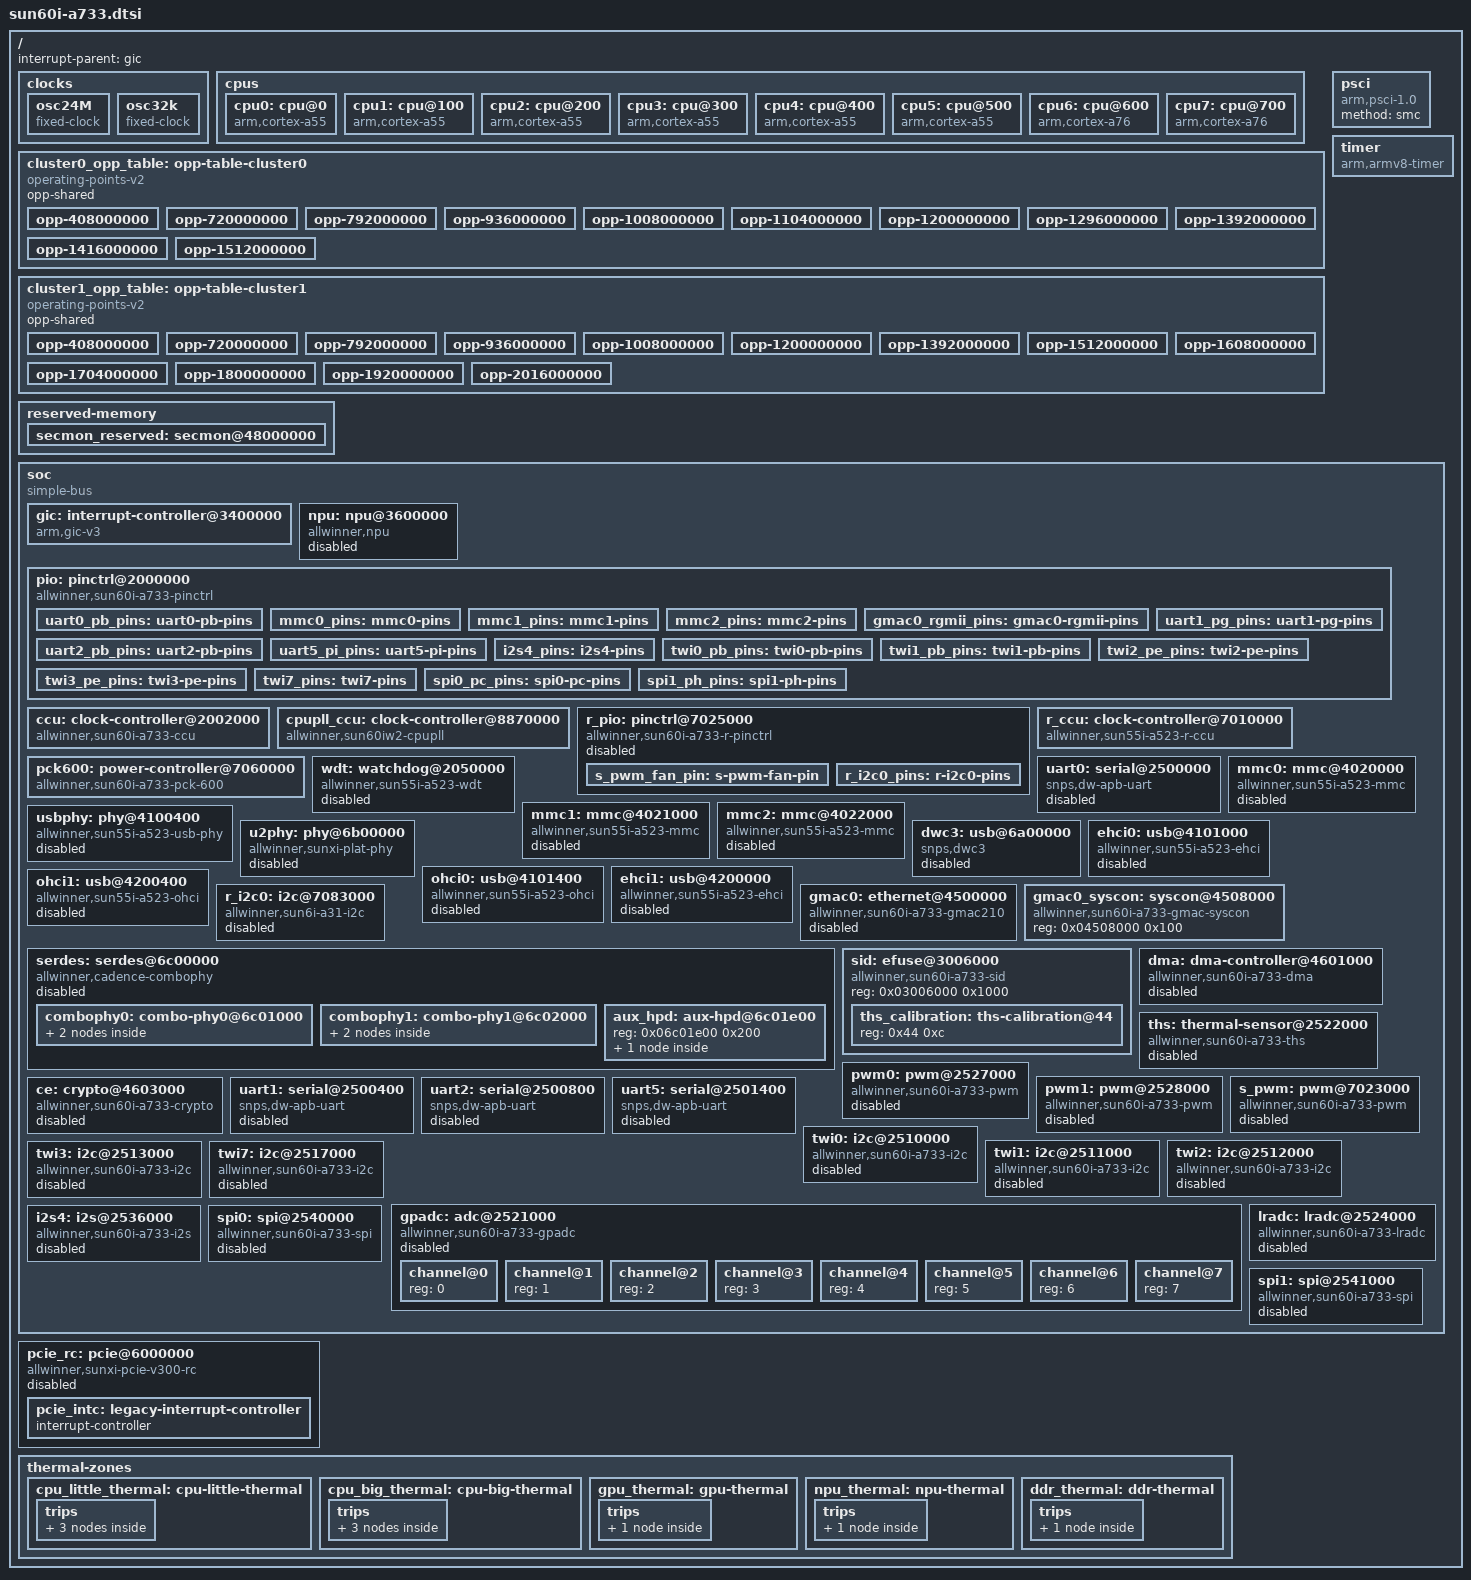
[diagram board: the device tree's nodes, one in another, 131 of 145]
// SPDX-License-Identifier: (GPL-2.0-only OR MIT)
/*
 * Copyright (C) 2026 Alastair D'Silva <alastair@d-silva.org>
 */

#include <dt-bindings/interrupt-controller/arm-gic.h>
#include <dt-bindings/clock/sun60i-a733-ccu.h>
#include <dt-bindings/clock/sun55i-a523-r-ccu.h>
#include <dt-bindings/reset/sun60i-a733-ccu.h>
#include <dt-bindings/reset/sun55i-a523-r-ccu.h>
#include <dt-bindings/power/allwinner,sun60i-a733-pck-600.h>
#include <dt-bindings/thermal/thermal.h>

#ifndef CLK_PLL_CPU_L
#define CLK_PLL_CPU_L 1
#endif
#ifndef CLK_PLL_CPU_B
#define CLK_PLL_CPU_B 2
#endif

/ {
	interrupt-parent = <&gic>;
	#address-cells = <2>;
	#size-cells = <2>;

	clocks {
		osc24M: osc24M {
			#clock-cells = <0>;
			compatible = "fixed-clock";
			clock-frequency = <24000000>;
			clock-output-names = "osc24M";
		};

		osc32k: osc32k {
			#clock-cells = <0>;
			compatible = "fixed-clock";
			clock-frequency = <32768>;
			clock-output-names = "osc32k";
		};
	};

	cpus {
		#address-cells = <2>;
		#size-cells = <0>;

		cpu0: cpu@0 {
			compatible = "arm,cortex-a55";
			device_type = "cpu";
			reg = <0x0 0x0>;
			enable-method = "psci";
			clocks = <&cpupll_ccu CLK_PLL_CPU_L>;
			operating-points-v2 = <&cluster0_opp_table>;
		};

		cpu1: cpu@100 {
			compatible = "arm,cortex-a55";
			device_type = "cpu";
			reg = <0x0 0x100>;
			enable-method = "psci";
			clocks = <&cpupll_ccu CLK_PLL_CPU_L>;
			operating-points-v2 = <&cluster0_opp_table>;
		};

		cpu2: cpu@200 {
			compatible = "arm,cortex-a55";
			device_type = "cpu";
			reg = <0x0 0x200>;
			enable-method = "psci";
			clocks = <&cpupll_ccu CLK_PLL_CPU_L>;
			operating-points-v2 = <&cluster0_opp_table>;
		};

		cpu3: cpu@300 {
			compatible = "arm,cortex-a55";
			device_type = "cpu";
			reg = <0x0 0x300>;
			enable-method = "psci";
			clocks = <&cpupll_ccu CLK_PLL_CPU_L>;
			operating-points-v2 = <&cluster0_opp_table>;
		};

		cpu4: cpu@400 {
			compatible = "arm,cortex-a55";
			device_type = "cpu";
			reg = <0x0 0x400>;
			enable-method = "psci";
			clocks = <&cpupll_ccu CLK_PLL_CPU_L>;
			operating-points-v2 = <&cluster0_opp_table>;
		};

		cpu5: cpu@500 {
			compatible = "arm,cortex-a55";
			device_type = "cpu";
			reg = <0x0 0x500>;
			enable-method = "psci";
			clocks = <&cpupll_ccu CLK_PLL_CPU_L>;
			operating-points-v2 = <&cluster0_opp_table>;
		};

		cpu6: cpu@600 {
			compatible = "arm,cortex-a76";
			device_type = "cpu";
			reg = <0x0 0x600>;
			enable-method = "psci";
			clocks = <&cpupll_ccu CLK_PLL_CPU_B>;
			operating-points-v2 = <&cluster1_opp_table>;
		};

		cpu7: cpu@700 {
			compatible = "arm,cortex-a76";
			device_type = "cpu";
			reg = <0x0 0x700>;
			enable-method = "psci";
			clocks = <&cpupll_ccu CLK_PLL_CPU_B>;
			operating-points-v2 = <&cluster1_opp_table>;
		};
	};

	cluster0_opp_table: opp-table-cluster0 {
		compatible = "operating-points-v2";
		opp-shared;

		opp-408000000 {
			opp-hz = /bits/ 64 <408000000>;
			opp-microvolt = <800000>;
			clock-latency-ns = <244144>;
		};

		opp-720000000 {
			opp-hz = /bits/ 64 <720000000>;
			opp-microvolt = <800000>;
			clock-latency-ns = <244144>;
		};

		opp-792000000 {
			opp-hz = /bits/ 64 <792000000>;
			opp-microvolt = <800000>;
			clock-latency-ns = <244144>;
		};

		opp-936000000 {
			opp-hz = /bits/ 64 <936000000>;
			opp-microvolt = <800000>;
			clock-latency-ns = <244144>;
		};

		opp-1008000000 {
			opp-hz = /bits/ 64 <1008000000>;
			opp-microvolt = <800000>;
			clock-latency-ns = <244144>;
		};

		opp-1104000000 {
			opp-hz = /bits/ 64 <1104000000>;
			opp-microvolt = <800000>;
			clock-latency-ns = <244144>;
		};

		opp-1200000000 {
			opp-hz = /bits/ 64 <1200000000>;
			opp-microvolt = <850000>;
			clock-latency-ns = <244144>;
		};

		opp-1296000000 {
			opp-hz = /bits/ 64 <1296000000>;
			opp-microvolt = <900000>;
			clock-latency-ns = <244144>;
		};

		opp-1392000000 {
			opp-hz = /bits/ 64 <1392000000>;
			opp-microvolt = <950000>;
			clock-latency-ns = <244144>;
		};

		opp-1416000000 {
			opp-hz = /bits/ 64 <1416000000>;
			opp-microvolt = <960000>;
			clock-latency-ns = <244144>;
		};

		opp-1512000000 {
			opp-hz = /bits/ 64 <1512000000>;
			opp-microvolt = <1000000>;
			clock-latency-ns = <244144>;
		};
	};

	cluster1_opp_table: opp-table-cluster1 {
		compatible = "operating-points-v2";
		opp-shared;

		opp-408000000 {
			opp-hz = /bits/ 64 <408000000>;
			opp-microvolt = <800000>;
			clock-latency-ns = <244144>;
		};

		opp-720000000 {
			opp-hz = /bits/ 64 <720000000>;
			opp-microvolt = <800000>;
			clock-latency-ns = <244144>;
		};

		opp-792000000 {
			opp-hz = /bits/ 64 <792000000>;
			opp-microvolt = <800000>;
			clock-latency-ns = <244144>;
		};

		opp-936000000 {
			opp-hz = /bits/ 64 <936000000>;
			opp-microvolt = <800000>;
			clock-latency-ns = <244144>;
		};

		opp-1008000000 {
			opp-hz = /bits/ 64 <1008000000>;
			opp-microvolt = <800000>;
			clock-latency-ns = <244144>;
		};

		opp-1200000000 {
			opp-hz = /bits/ 64 <1200000000>;
			opp-microvolt = <800000>;
			clock-latency-ns = <244144>;
		};

		opp-1392000000 {
			opp-hz = /bits/ 64 <1392000000>;
			opp-microvolt = <850000>;
			clock-latency-ns = <244144>;
		};

		opp-1512000000 {
			opp-hz = /bits/ 64 <1512000000>;
			opp-microvolt = <900000>;
			clock-latency-ns = <244144>;
		};

		opp-1608000000 {
			opp-hz = /bits/ 64 <1608000000>;
			opp-microvolt = <950000>;
			clock-latency-ns = <244144>;
		};

		opp-1704000000 {
			opp-hz = /bits/ 64 <1704000000>;
			opp-microvolt = <1000000>;
			clock-latency-ns = <244144>;
		};

		opp-1800000000 {
			opp-hz = /bits/ 64 <1800000000>;
			opp-microvolt = <1050000>;
			clock-latency-ns = <244144>;
		};

		opp-1920000000 {
			opp-hz = /bits/ 64 <1920000000>;
			opp-microvolt = <1100000>;
			clock-latency-ns = <244144>;
		};

		opp-2016000000 {
			opp-hz = /bits/ 64 <2016000000>;
			opp-microvolt = <1150000>;
			clock-latency-ns = <244144>;
		};
	};

	psci {
		compatible = "arm,psci-1.0";
		method = "smc";
	};

	timer {
		compatible = "arm,armv8-timer";
		interrupts = <GIC_PPI 13 IRQ_TYPE_LEVEL_LOW>,
			     <GIC_PPI 14 IRQ_TYPE_LEVEL_LOW>,
			     <GIC_PPI 11 IRQ_TYPE_LEVEL_LOW>,
			     <GIC_PPI 10 IRQ_TYPE_LEVEL_LOW>;
	};

	reserved-memory {
		#address-cells = <2>;
		#size-cells = <2>;
		ranges;

		secmon_reserved: secmon@48000000 {
			reg = <0x0 0x48000000 0x0 0x01000000>;
			no-map;
		};
	};

	soc {
		compatible = "simple-bus";
		#address-cells = <1>;
		#size-cells = <1>;
		ranges = <0x0 0x0 0x0 0x40000000>;

		gic: interrupt-controller@3400000 {
			compatible = "arm,gic-v3";
			reg = <0x03400000 0x10000>,
			      <0x03460000 0x100000>;
			interrupts = <GIC_PPI 9 IRQ_TYPE_LEVEL_HIGH>;
			interrupt-controller;
			#interrupt-cells = <3>;
		};

		npu: npu@3600000 {
			compatible = "allwinner,npu";
			reg = <0x03600000 0x1000>;
			interrupts = <GIC_SPI 65 IRQ_TYPE_LEVEL_HIGH>;
			interrupt-names = "npu";
			clocks = <&ccu CLK_NPU>, <&ccu CLK_PLL_PERIPH0_800M>, <&ccu CLK_BUS_NPU>;
			clock-names = "clk_npu", "clk_parent", "clk_bus";
			resets = <&ccu RST_BUS_NPU_CORE>, <&ccu RST_BUS_NPU_AXI>, <&ccu RST_BUS_NPU_AHB>;
			reset-names = "npu_rst", "npu_axi_rst", "npu_ahb_rst";
			power-domains = <&pck600 PD_NPU>;
			assigned-clocks = <&ccu CLK_NPU>;
			assigned-clock-parents = <&ccu CLK_PLL_PERIPH0_800M>;
			assigned-clock-rates = <800000000>;
			status = "disabled";
		};

		pio: pinctrl@2000000 {
			compatible = "allwinner,sun60i-a733-pinctrl",
				     "allwinner,sun55i-a523-pinctrl";
			reg = <0x02000000 0x800>;
			interrupts = <GIC_SPI 67 IRQ_TYPE_LEVEL_HIGH>,
				     <GIC_SPI 69 IRQ_TYPE_LEVEL_HIGH>,
				     <GIC_SPI 71 IRQ_TYPE_LEVEL_HIGH>,
				     <GIC_SPI 73 IRQ_TYPE_LEVEL_HIGH>,
				     <GIC_SPI 75 IRQ_TYPE_LEVEL_HIGH>,
				     <GIC_SPI 77 IRQ_TYPE_LEVEL_HIGH>,
				     <GIC_SPI 79 IRQ_TYPE_LEVEL_HIGH>,
				     <GIC_SPI 81 IRQ_TYPE_LEVEL_HIGH>,
				     <GIC_SPI 83 IRQ_TYPE_LEVEL_HIGH>,
				     <GIC_SPI 85 IRQ_TYPE_LEVEL_HIGH>,
				     <GIC_SPI 140 IRQ_TYPE_LEVEL_HIGH>;
			clocks = <&ccu CLK_APB1>, <&osc24M>, <&osc32k>;
			clock-names = "apb", "hosc", "losc";
			#gpio-cells = <3>;
			gpio-controller;
			interrupt-controller;
			#interrupt-cells = <3>;

			uart0_pb_pins: uart0-pb-pins {
				pins = "PB9", "PB10";
				function = "uart0";
				allwinner,pinmux = <2>;
			};

			mmc0_pins: mmc0-pins {
				pins = "PF0", "PF1", "PF2", "PF3", "PF4", "PF5";
				function = "mmc0";
				allwinner,pinmux = <2>;
				drive-strength = <30>;
				bias-pull-up;
			};

			mmc1_pins: mmc1-pins {
				pins = "PG0", "PG1", "PG2", "PG3", "PG4", "PG5";
				function = "mmc1";
				allwinner,pinmux = <2>;
				drive-strength = <30>;
				bias-pull-up;
			};

			mmc2_pins: mmc2-pins {
				pins = "PC0", "PC1", "PC5", "PC6", "PC7",
				       "PC8", "PC9", "PC10", "PC11", "PC12", "PC13";
				function = "mmc2";
				allwinner,pinmux = <3>;
				drive-strength = <30>;
				bias-pull-up;
			};

			gmac0_rgmii_pins: gmac0-rgmii-pins {
				pins = "PH0", "PH1", "PH2", "PH3",
				       "PH4", "PH5", "PH6", "PH7",
				       "PH8", "PH9", "PH10", "PH11",
				       "PH12", "PH13", "PH14", "PH15";
				function = "gmac0";
				allwinner,pinmux = <5>;
				drive-strength = <40>;
				bias-pull-up;
			};

			uart1_pg_pins: uart1-pg-pins {
				pins = "PG6", "PG7", "PG8", "PG9";
				function = "uart1";
				allwinner,pinmux = <2>;
			};

			uart2_pb_pins: uart2-pb-pins {
				pins = "PB0", "PB1";
				function = "uart2";
				allwinner,pinmux = <2>;
			};

			uart5_pi_pins: uart5-pi-pins {
				pins = "PI8", "PI9";
				function = "uart5";
				allwinner,pinmux = <3>;
			};

			i2s4_pins: i2s4-pins {
				pins = "PK0", "PK1", "PK2", "PK3", "PK4";
				function = "i2s4";
				allwinner,pinmux = <4>;
			};

			twi0_pb_pins: twi0-pb-pins {
				pins = "PB2", "PB3";
				function = "twi0";
				allwinner,pinmux = <8>;
			};

			twi1_pb_pins: twi1-pb-pins {
				pins = "PB4", "PB5";
				function = "twi1";
				allwinner,pinmux = <8>;
			};

			twi2_pe_pins: twi2-pe-pins {
				pins = "PE1", "PE2";
				function = "twi2";
				allwinner,pinmux = <2>;
			};

			twi3_pe_pins: twi3-pe-pins {
				pins = "PE3", "PE4";
				function = "twi3";
				allwinner,pinmux = <2>;
			};

			twi7_pins: twi7-pins {
				pins = "PJ22", "PJ23";
				function = "twi7";
				allwinner,pinmux = <6>;
				drive-strength = <10>;
				bias-pull-up;
			};

			spi0_pc_pins: spi0-pc-pins {
				pins = "PC2", "PC3", "PC4", "PC12";
				function = "spi0";
				allwinner,pinmux = <5>;
			};

			spi1_ph_pins: spi1-ph-pins {
				pins = "PH3", "PH4", "PH5", "PH6";
				function = "spi1";
				allwinner,pinmux = <7>;
			};
		};

		ccu: clock-controller@2002000 {
			compatible = "allwinner,sun60i-a733-ccu";
			reg = <0x02002000 0x3000>;
			clocks = <&osc24M>, <&osc32k>, <&osc32k>, <&osc32k>;

			clock-names = "hosc", "losc", "iosc", "losc-fanout";
			#clock-cells = <1>;
			#reset-cells = <1>;
		};

		cpupll_ccu: clock-controller@8870000 {
			compatible = "allwinner,sun60iw2-cpupll";
			reg = <0x08870000 0x3034>;
			clocks = <&osc24M>;
			clock-names = "dcxo";
			#clock-cells = <1>;
			#reset-cells = <1>;
		};

		r_pio: pinctrl@7025000 {
			compatible = "allwinner,sun60i-a733-r-pinctrl",
				     "allwinner,sun55i-a523-r-pinctrl";
			reg = <0x07025000 0x800>;
			interrupts = <GIC_SPI 198 IRQ_TYPE_LEVEL_HIGH>,
				     <GIC_SPI 200 IRQ_TYPE_LEVEL_HIGH>;
			clocks = <&r_ccu CLK_R_APB0>, <&osc24M>, <&osc32k>;
			clock-names = "apb", "hosc", "losc";
			#gpio-cells = <3>;
			gpio-controller;
			interrupt-controller;
			#interrupt-cells = <3>;
			status = "disabled";

			s_pwm_fan_pin: s-pwm-fan-pin {
				pins = "PL9";
				function = "s_pwm";
				allwinner,pinmux = <6>;
			};

			r_i2c0_pins: r-i2c0-pins {
				pins = "PL0", "PL1";
				function = "r_i2c0";
				allwinner,pinmux = <2>;
				drive-strength = <10>;
				bias-pull-up;
			};
		};

		r_ccu: clock-controller@7010000 {
			compatible = "allwinner,sun55i-a523-r-ccu";
			reg = <0x07010000 0x1000>;
			clocks = <&osc24M>, <&osc32k>, <&osc32k>, <&ccu CLK_PLL_PERIPH0_200M>;
			clock-names = "hosc", "losc", "iosc", "pll-periph";
			#clock-cells = <1>;
			#reset-cells = <1>;
		};

		pck600: power-controller@7060000 {
			compatible = "allwinner,sun60i-a733-pck-600";
			reg = <0x07060000 0xb000>;
			clocks = <&r_ccu CLK_BUS_R_PPU0>;
			#power-domain-cells = <1>;
		};

		wdt: watchdog@2050000 {
			compatible = "allwinner,sun55i-a523-wdt",
				     "allwinner,sun20i-d1-wdt";
			reg = <0x02050000 0x20>;
			interrupts = <GIC_SPI 23 IRQ_TYPE_LEVEL_HIGH>;
			clocks = <&osc24M>;
			status = "disabled";
		};

		uart0: serial@2500000 {
			compatible = "snps,dw-apb-uart";
			reg = <0x02500000 0x400>;
			interrupts = <GIC_SPI 2 IRQ_TYPE_LEVEL_HIGH>;
			reg-shift = <2>;
			reg-io-width = <4>;
			clocks = <&ccu CLK_BUS_UART0>;
			resets = <&ccu RST_BUS_UART0>;
			status = "disabled";
		};

		mmc0: mmc@4020000 {
			compatible = "allwinner,sun55i-a523-mmc",
				     "allwinner,sun20i-d1-mmc";
			reg = <0x04020000 0x1000>;
			clocks = <&ccu CLK_BUS_MMC0>, <&ccu CLK_MMC0>;
			clock-names = "ahb", "mmc";
			resets = <&ccu RST_BUS_MMC0>;
			reset-names = "ahb";
			interrupts = <GIC_SPI 161 IRQ_TYPE_LEVEL_HIGH>;
			pinctrl-names = "default";
			pinctrl-0 = <&mmc0_pins>;
			status = "disabled";

			max-frequency = <150000000>;
			cap-sd-highspeed;
			cap-mmc-highspeed;
			#address-cells = <1>;
			#size-cells = <0>;
		};

		mmc1: mmc@4021000 {
			compatible = "allwinner,sun55i-a523-mmc",
				     "allwinner,sun20i-d1-mmc";
			reg = <0x04021000 0x1000>;
			clocks = <&ccu CLK_BUS_MMC1>, <&ccu CLK_MMC1>;
			clock-names = "ahb", "mmc";
			resets = <&ccu RST_BUS_MMC1>;
			reset-names = "ahb";
			interrupts = <GIC_SPI 162 IRQ_TYPE_LEVEL_HIGH>;
			pinctrl-names = "default";
			pinctrl-0 = <&mmc1_pins>;
			status = "disabled";

			max-frequency = <150000000>;
			cap-sd-highspeed;
			cap-sdio-irq;
			#address-cells = <1>;
			#size-cells = <0>;
		};

		mmc2: mmc@4022000 {
			compatible = "allwinner,sun55i-a523-mmc",
				     "allwinner,sun20i-d1-mmc";
			reg = <0x04022000 0x1000>;
			clocks = <&ccu CLK_BUS_MMC2>, <&ccu CLK_MMC2>;
			clock-names = "ahb", "mmc";
			resets = <&ccu RST_BUS_MMC2>;
			reset-names = "ahb";
			interrupts = <GIC_SPI 163 IRQ_TYPE_LEVEL_HIGH>;
			pinctrl-names = "default";
			pinctrl-0 = <&mmc2_pins>;
			status = "disabled";

			max-frequency = <150000000>;
			cap-sd-highspeed;
			cap-mmc-highspeed;
			#address-cells = <1>;
			#size-cells = <0>;
		};

		usbphy: phy@4100400 {
			compatible = "allwinner,sun55i-a523-usb-phy";
			reg = <0x04100400 0x14>,
			      <0x04101800 0x4>,
			      <0x04200800 0x4>;
			reg-names = "phy_ctrl",
				    "pmu0",
				    "pmu1";
			clocks = <&ccu CLK_USB_OHCI0>,
				 <&ccu CLK_USB_OHCI1>;
			clock-names = "usb0_phy",
				      "usb1_phy";
			resets = <&ccu RST_USB_PHY0>,
				 <&ccu RST_USB_PHY1>;
			reset-names = "usb0_reset",
				      "usb1_reset";
			status = "disabled";
			#phy-cells = <1>;
		};

		u2phy: phy@6b00000 {
			compatible = "allwinner,sunxi-plat-phy";
			reg = <0x06b00000 0x800>,
			      <0x03000000 0x300>;
			reg-names = "u2_base", "res_base";
			clocks = <&ccu CLK_BUS_OTG>, <&osc24M>;
			clock-names = "phy_clk", "res_dcap";
			aw,rext_mode = <2>;
			aw,phy_tune_param = <0x143338D6>;
			#phy-cells = <0>;
			status = "disabled";
		};

		dwc3: usb@6a00000 {
			compatible = "snps,dwc3";
			reg = <0x06a00000 0x100000>;
			interrupts = <GIC_SPI 155 IRQ_TYPE_LEVEL_HIGH>;
			clocks = <&ccu CLK_BUS_OTG>, <&ccu CLK_USB3_REF>;
			clock-names = "bus_clk", "ref";
			assigned-clocks = <&ccu CLK_USB3_REF>;
			assigned-clock-rates = <24000000>;
			resets = <&ccu RST_BUS_3>, <&ccu RST_BUS_PCIE_USB3>;
			reset-names = "bus", "dwc3";
			maximum-speed = "super-speed-plus";
			phy_type = "utmi";
			dr_mode = "host";
			snps,dis_enblslpm_quirk;
			snps,dis-u1-entry-quirk;
			snps,dis-u2-entry-quirk;
			snps,dis_u2_susphy_quirk;
			snps,dis_u3_susphy_quirk;
			phys = <&u2phy>, <&combo0_usb>;
			phy-names = "usb2-phy", "usb3-phy";
			status = "disabled";
		};

		ehci0: usb@4101000 {
			compatible = "allwinner,sun55i-a523-ehci",
				     "generic-ehci";
			reg = <0x04101000 0x100>;
			interrupts = <GIC_SPI 157 IRQ_TYPE_LEVEL_HIGH>;
			clocks = <&ccu CLK_BUS_OHCI0>,
				 <&ccu CLK_BUS_EHCI0>,
				 <&ccu CLK_USB_OHCI0>;
			resets = <&ccu RST_BUS_OHCI0>,
				 <&ccu RST_BUS_EHCI0>;
			phys = <&usbphy 0>;
			phy-names = "usb";
			status = "disabled";
		};

		ohci0: usb@4101400 {
			compatible = "allwinner,sun55i-a523-ohci",
				     "generic-ohci";
			reg = <0x04101400 0x100>;
			interrupts = <GIC_SPI 158 IRQ_TYPE_LEVEL_HIGH>;
			clocks = <&ccu CLK_BUS_OHCI0>,
				 <&ccu CLK_USB_OHCI0>;
			resets = <&ccu RST_BUS_OHCI0>;
			phys = <&usbphy 0>;
			phy-names = "usb";
			status = "disabled";
		};

		ehci1: usb@4200000 {
			compatible = "allwinner,sun55i-a523-ehci",
				     "generic-ehci";
			reg = <0x04200000 0x100>;
			interrupts = <GIC_SPI 159 IRQ_TYPE_LEVEL_HIGH>;
			clocks = <&ccu CLK_BUS_OHCI1>,
				 <&ccu CLK_BUS_EHCI1>,
				 <&ccu CLK_USB_OHCI1>;
			resets = <&ccu RST_BUS_OHCI1>,
				 <&ccu RST_BUS_EHCI1>;
			phys = <&usbphy 1>;
			phy-names = "usb";
			status = "disabled";
		};

		ohci1: usb@4200400 {
			compatible = "allwinner,sun55i-a523-ohci",
				     "generic-ohci";
			reg = <0x04200400 0x100>;
			interrupts = <GIC_SPI 160 IRQ_TYPE_LEVEL_HIGH>;
			clocks = <&ccu CLK_BUS_OHCI1>,
				 <&ccu CLK_USB_OHCI1>;
			resets = <&ccu RST_BUS_OHCI1>;
			phys = <&usbphy 1>;
			phy-names = "usb";
			status = "disabled";
		};

		gmac0: ethernet@4500000 {
			compatible = "allwinner,sun60i-a733-gmac210";
			reg = <0x04500000 0x4000>;
			interrupts = <GIC_SPI 172 IRQ_TYPE_LEVEL_HIGH>,
				     <GIC_SPI 178 IRQ_TYPE_LEVEL_HIGH>,
				     <GIC_SPI 173 IRQ_TYPE_LEVEL_HIGH>,
				     <GIC_SPI 174 IRQ_TYPE_LEVEL_HIGH>;
			interrupt-names = "macirq", "eth_lpi", "tx0_irq", "rx0_irq";
			clocks = <&ccu CLK_BUS_EMAC0>, <&ccu CLK_BUS_EMAC0>, <&ccu CLK_BUS_EMAC0>;
			clock-names = "stmmaceth", "pclk", "ptp_ref";
			resets = <&ccu RST_BUS_EMAC0>;
			reset-names = "stmmaceth";
			syscon = <&gmac0_syscon>;
			status = "disabled";
		};

		gmac0_syscon: syscon@4508000 {
			compatible = "allwinner,sun60i-a733-gmac-syscon", "syscon";
			reg = <0x04508000 0x100>;
		};

		r_i2c0: i2c@7083000 {
			compatible = "allwinner,sun6i-a31-i2c";
			reg = <0x07083000 0x400>;
			interrupts = <GIC_SPI 203 IRQ_TYPE_LEVEL_HIGH>;
			clocks = <&r_ccu CLK_BUS_R_I2C0>;
			clock-names = "bus";
			resets = <&r_ccu RST_BUS_R_I2C0>;
			#address-cells = <1>;
			#size-cells = <0>;
			status = "disabled";
		};

		serdes: serdes@6c00000 {
			compatible = "allwinner,cadence-combophy";
			reg = <0x06c00000 0x2000>,
			      <0x06c06000 0x2000>,
			      <0x0709016c 0x4>;
			clocks = <&ccu CLK_SERDES_PHY_CFG>, <&osc24M>, <&osc24M>;
			clock-names = "serdes-clk", "dcxo-serdes0-clk", "dcxo-serdes1-clk";
			resets = <&ccu RST_BUS_SERDES>;
			reset-names = "serdes-reset";
			power-domains = <&pck600 PD_PCIE>;
			udp-disable;
			#address-cells = <1>;
			#size-cells = <1>;
			ranges;
			status = "disabled";



			combophy0: combo-phy0@6c01000 {
				reg = <0x06c01000 0xa00>,
				      <0x06c80000 0x20000>;
				lane_remap = <0x00 0x01 0x02 0x03>;
				lane_invert = <0x00 0x00 0x00 0x00>;
				combo0_dp: combo0-dp-phy {
					#phy-cells = <0>;
					status = "okay";
				};
				combo0_usb: combo0-usb-phy {
					#phy-cells = <0>;
					status = "okay";
				};
			};

			combophy1: combo-phy1@6c02000 {
				reg = <0x06c02000 0xa00>,
				      <0x06ca0000 0x20000>;
				lane_remap = <0x00 0x01 0x02 0x03>;
				lane_invert = <0x00 0x00 0x00 0x00>;
				combo1_usb: combo1-usb-phy {
					#phy-cells = <0>;
					status = "okay";
				};
				combo1_pcie: combo1-pcie-phy {
					#phy-cells = <0>;
					status = "okay";
				};
			};

			aux_hpd: aux-hpd@6c01e00 {
				reg = <0x06c01e00 0x200>;
				aux_hpd_phy: aux-hpd-phy {
					#phy-cells = <0>;
					status = "okay";
				};
			};
		};

		sid: efuse@3006000 {
			compatible = "allwinner,sun60i-a733-sid",
				     "allwinner,sun55i-a523-sid",
				     "allwinner,sun50i-a64-sid";
			reg = <0x03006000 0x1000>;
			#address-cells = <1>;
			#size-cells = <1>;

			ths_calibration: ths-calibration@44 {
				reg = <0x44 0xc>;
			};
		};

		dma: dma-controller@4601000 {
			compatible = "allwinner,sun60i-a733-dma",
				     "allwinner,sun55i-a523-dma",
				     "allwinner,sun50i-a100-dma";
			reg = <0x04601000 0x1000>;
			interrupts = <GIC_SPI 111 IRQ_TYPE_LEVEL_HIGH>;
			clocks = <&ccu CLK_BUS_DMA>, <&ccu CLK_MBUS_DMA>;
			clock-names = "bus", "mbus";
			dma-channels = <16>;
			dma-requests = <64>;
			resets = <&ccu RST_BUS_DMA>;
			#dma-cells = <1>;
			status = "disabled";
		};

		ths: thermal-sensor@2522000 {
			compatible = "allwinner,sun60i-a733-ths";
			reg = <0x02522000 0x500>;
			interrupts = <GIC_SPI 40 IRQ_TYPE_LEVEL_HIGH>;
			clocks = <&ccu CLK_BUS_THS>, <&ccu CLK_GPADC0>;
			clock-names = "bus", "mod";
			resets = <&ccu RST_BUS_THS>;
			nvmem-cells = <&ths_calibration>;
			nvmem-cell-names = "calibration";
			#thermal-sensor-cells = <1>;
			status = "disabled";
		};

		pwm0: pwm@2527000 {
			compatible = "allwinner,sun60i-a733-pwm",
				     "allwinner,sun55i-a523-pwm",
				     "allwinner,sun50i-h616-pwm";
			reg = <0x02527000 0x400>;
			interrupts = <GIC_SPI 24 IRQ_TYPE_LEVEL_HIGH>;
			clocks = <&ccu CLK_BUS_PWM0>;
			clock-names = "bus";
			resets = <&ccu RST_BUS_PWM0>;
			pwm-number = <10>;
			pwm-base = <0>;
			#pwm-cells = <3>;
			status = "disabled";
		};

		pwm1: pwm@2528000 {
			compatible = "allwinner,sun60i-a733-pwm",
				     "allwinner,sun55i-a523-pwm",
				     "allwinner,sun50i-h616-pwm";
			reg = <0x02528000 0x400>;
			interrupts = <GIC_SPI 25 IRQ_TYPE_LEVEL_HIGH>;
			clocks = <&ccu CLK_BUS_PWM1>;
			clock-names = "bus";
			resets = <&ccu RST_BUS_PWM1>;
			pwm-number = <10>;
			pwm-base = <10>;
			#pwm-cells = <3>;
			status = "disabled";
		};

		s_pwm: pwm@7023000 {
			compatible = "allwinner,sun60i-a733-pwm",
				     "allwinner,sun55i-a523-pwm",
				     "allwinner,sun50i-h616-pwm";
			reg = <0x07023000 0x400>;
			interrupts = <GIC_SPI 207 IRQ_TYPE_LEVEL_HIGH>;
			clocks = <&r_ccu CLK_BUS_R_PWMCTRL>, <&r_ccu CLK_R_PWMCTRL>;
			clock-names = "bus", "mod";
			resets = <&r_ccu RST_BUS_R_PWMCTRL>;
			pwm-number = <10>;
			pwm-base = <20>;
			#pwm-cells = <3>;
			status = "disabled";
		};

		ce: crypto@4603000 {
			compatible = "allwinner,sun60i-a733-crypto",
				     "allwinner,sun55i-a523-crypto";
			reg = <0x04603000 0x1000>;
			interrupts = <GIC_SPI 168 IRQ_TYPE_LEVEL_HIGH>;
			clocks = <&ccu CLK_BUS_CE>, <&ccu CLK_CE>,
				 <&ccu CLK_MBUS_CE>, <&osc24M>;
			clock-names = "bus", "mod", "ram", "trng";
			resets = <&ccu RST_BUS_CE>;
			status = "disabled";
		};

		uart1: serial@2500400 {
			compatible = "snps,dw-apb-uart";
			reg = <0x02500400 0x400>;
			interrupts = <GIC_SPI 3 IRQ_TYPE_LEVEL_HIGH>;
			reg-shift = <2>;
			reg-io-width = <4>;
			clocks = <&ccu CLK_BUS_UART1>;
			resets = <&ccu RST_BUS_UART1>;
			dmas = <&dma 23>, <&dma 23>;
			dma-names = "tx", "rx";
			status = "disabled";
		};

		uart2: serial@2500800 {
			compatible = "snps,dw-apb-uart";
			reg = <0x02500800 0x400>;
			interrupts = <GIC_SPI 4 IRQ_TYPE_LEVEL_HIGH>;
			reg-shift = <2>;
			reg-io-width = <4>;
			clocks = <&ccu CLK_BUS_UART2>;
			resets = <&ccu RST_BUS_UART2>;
			dmas = <&dma 24>, <&dma 24>;
			dma-names = "tx", "rx";
			status = "disabled";
		};

		uart5: serial@2501400 {
			compatible = "snps,dw-apb-uart";
			reg = <0x02501400 0x400>;
			interrupts = <GIC_SPI 7 IRQ_TYPE_LEVEL_HIGH>;
			reg-shift = <2>;
			reg-io-width = <4>;
			clocks = <&ccu CLK_BUS_UART5>;
			resets = <&ccu RST_BUS_UART5>;
			dmas = <&dma 27>, <&dma 27>;
			dma-names = "tx", "rx";
			status = "disabled";
		};

		twi0: i2c@2510000 {
			compatible = "allwinner,sun60i-a733-i2c",
				     "allwinner,sun55i-a523-i2c",
				     "allwinner,sun6i-a31-i2c";
			reg = <0x02510000 0x400>;
			interrupts = <GIC_SPI 11 IRQ_TYPE_LEVEL_HIGH>;
			clocks = <&ccu CLK_BUS_I2C0>;
			resets = <&ccu RST_BUS_I2C0>;
			#address-cells = <1>;
			#size-cells = <0>;
			status = "disabled";
		};

		twi1: i2c@2511000 {
			compatible = "allwinner,sun60i-a733-i2c",
				     "allwinner,sun55i-a523-i2c",
				     "allwinner,sun6i-a31-i2c";
			reg = <0x02511000 0x400>;
			interrupts = <GIC_SPI 12 IRQ_TYPE_LEVEL_HIGH>;
			clocks = <&ccu CLK_BUS_I2C1>;
			resets = <&ccu RST_BUS_I2C1>;
			#address-cells = <1>;
			#size-cells = <0>;
			status = "disabled";
		};

		twi2: i2c@2512000 {
			compatible = "allwinner,sun60i-a733-i2c",
				     "allwinner,sun55i-a523-i2c",
				     "allwinner,sun6i-a31-i2c";
			reg = <0x02512000 0x400>;
			interrupts = <GIC_SPI 13 IRQ_TYPE_LEVEL_HIGH>;
			clocks = <&ccu CLK_BUS_I2C2>;
			resets = <&ccu RST_BUS_I2C2>;
			#address-cells = <1>;
			#size-cells = <0>;
			status = "disabled";
		};

		twi3: i2c@2513000 {
			compatible = "allwinner,sun60i-a733-i2c",
				     "allwinner,sun55i-a523-i2c",
				     "allwinner,sun6i-a31-i2c";
			reg = <0x02513000 0x400>;
			interrupts = <GIC_SPI 14 IRQ_TYPE_LEVEL_HIGH>;
			clocks = <&ccu CLK_BUS_I2C3>;
			resets = <&ccu RST_BUS_I2C3>;
			#address-cells = <1>;
			#size-cells = <0>;
			status = "disabled";
		};

		twi7: i2c@2517000 {
			compatible = "allwinner,sun60i-a733-i2c",
				     "allwinner,sun55i-a523-i2c",
				     "allwinner,sun6i-a31-i2c";
			reg = <0x02517000 0x400>;
			interrupts = <GIC_SPI 18 IRQ_TYPE_LEVEL_HIGH>;
			clocks = <&ccu CLK_BUS_I2C7>;
			resets = <&ccu RST_BUS_I2C7>;
			#address-cells = <1>;
			#size-cells = <0>;
			status = "disabled";
		};

		gpadc: adc@2521000 {
			compatible = "allwinner,sun60i-a733-gpadc",
				     "allwinner,sun55i-a523-gpadc",
				     "allwinner,sun20i-d1-gpadc";
			reg = <0x02521000 0x400>;
			interrupts = <GIC_SPI 38 IRQ_TYPE_LEVEL_HIGH>;
			clocks = <&ccu CLK_BUS_GPADC0>, <&ccu CLK_GPADC0>;
			clock-names = "bus", "mod";
			resets = <&ccu RST_BUS_GPADC0>;
			#io-channel-cells = <1>;
			#address-cells = <1>;
			#size-cells = <0>;
			status = "disabled";

			channel@0 {
				reg = <0>;
			};

			channel@1 {
				reg = <1>;
			};

			channel@2 {
				reg = <2>;
			};

			channel@3 {
				reg = <3>;
			};

			channel@4 {
				reg = <4>;
			};

			channel@5 {
				reg = <5>;
			};

			channel@6 {
				reg = <6>;
			};

			channel@7 {
				reg = <7>;
			};
		};

		lradc: lradc@2524000 {
			compatible = "allwinner,sun60i-a733-lradc",
				     "allwinner,sun55i-a523-lradc",
				     "allwinner,sun50i-h616-lradc";
			reg = <0x02524000 0x400>;
			interrupts = <GIC_SPI 37 IRQ_TYPE_LEVEL_HIGH>;
			clocks = <&ccu CLK_BUS_LRADC>;
			resets = <&ccu RST_BUS_LRADC>;
			status = "disabled";
		};

		i2s4: i2s@2536000 {
			compatible = "allwinner,sun60i-a733-i2s",
				     "allwinner,sun50i-h6-i2s";
			reg = <0x02536000 0x1000>;
			interrupts = <GIC_SPI 46 IRQ_TYPE_LEVEL_HIGH>;
			clocks = <&ccu CLK_BUS_I2S4>, <&ccu CLK_I2S4>;
			clock-names = "apb", "mod";
			resets = <&ccu RST_BUS_I2S4>;
			dmas = <&dma 7>, <&dma 7>;
			dma-names = "rx", "tx";
			#sound-dai-cells = <0>;
			status = "disabled";
		};

		spi0: spi@2540000 {
			compatible = "allwinner,sun60i-a733-spi",
				     "allwinner,sun50i-r329-spi";
			reg = <0x02540000 0x1000>;
			interrupts = <GIC_SPI 24 IRQ_TYPE_LEVEL_HIGH>;
			clocks = <&ccu CLK_BUS_SPI0>, <&ccu CLK_SPI0>;
			clock-names = "ahb", "mod";
			resets = <&ccu RST_BUS_SPI0>;
			#address-cells = <1>;
			#size-cells = <0>;
			status = "disabled";
		};

		spi1: spi@2541000 {
			compatible = "allwinner,sun60i-a733-spi",
				     "allwinner,sun50i-r329-spi";
			reg = <0x02541000 0x1000>;
			interrupts = <GIC_SPI 25 IRQ_TYPE_LEVEL_HIGH>;
			clocks = <&ccu CLK_BUS_SPI1>, <&ccu CLK_SPI1>;
			clock-names = "ahb", "mod";
			resets = <&ccu RST_BUS_SPI1>;
			#address-cells = <1>;
			#size-cells = <0>;
			status = "disabled";
		};
	};


	pcie_rc: pcie@6000000 {
		#address-cells = <3>;
		#size-cells = <2>;
		compatible = "allwinner,sunxi-pcie-v300-rc";
		bus-range = <0x0 0xff>;
		reg = <0x0 0x06000000 0x0 0x480000>;
		reg-names = "dbi";
		device_type = "pci";
		ranges = <0x00000800 0 0x20000000 0x0 0x20000000 0 0x01000000>,
			 <0x81000000 0 0x21000000 0x0 0x21000000 0 0x01000000>,
			 <0x82000000 0 0x22000000 0x0 0x22000000 0 0x06000000>;
		dma-ranges = <0x02000000 0x0 0x40000000 0x0 0x40000000 0x3 0xc0000000>;
		num-lanes = <1>;
		interrupts = <GIC_SPI 152 IRQ_TYPE_LEVEL_HIGH>,
			     <GIC_SPI 153 IRQ_TYPE_LEVEL_HIGH>,
			     <GIC_SPI 136 IRQ_TYPE_LEVEL_HIGH>,
			     <GIC_SPI 137 IRQ_TYPE_LEVEL_HIGH>,
			     <GIC_SPI 138 IRQ_TYPE_LEVEL_HIGH>,
			     <GIC_SPI 139 IRQ_TYPE_LEVEL_HIGH>,
			     <GIC_SPI 140 IRQ_TYPE_LEVEL_HIGH>,
			     <GIC_SPI 141 IRQ_TYPE_LEVEL_HIGH>,
			     <GIC_SPI 142 IRQ_TYPE_LEVEL_HIGH>,
			     <GIC_SPI 143 IRQ_TYPE_LEVEL_HIGH>;
		interrupt-names = "sii", "msi", "edma-w0", "edma-w1", "edma-w2", "edma-w3",
				  "edma-r0", "edma-r1", "edma-r2", "edma-r3";
		#interrupt-cells = <1>;
		interrupt-map-mask = <0 0 0 7>;
		interrupt-map = <0 0 0 1 &pcie_intc 0>,
				<0 0 0 2 &pcie_intc 1>,
				<0 0 0 3 &pcie_intc 2>,
				<0 0 0 4 &pcie_intc 3>;
		num-edma = <4>;
		max-link-speed = <3>;
		num-ib-windows = <16>;
		num-ob-windows = <16>;
		linux,pci-domain = <0>;
		power-domains = <&pck600 PD_PCIE>;
		clocks = <&ccu CLK_PCIE_AUX>, <&ccu CLK_PCIE_AXI_SLV>, <&ccu CLK_PCIE_ITS>;
		clock-names = "pclk_aux", "pclk_slv", "its";
		assigned-clocks = <&ccu CLK_PCIE_AXI_SLV>;
		assigned-clock-parents = <&ccu CLK_PLL_PERIPH0_400M>;
		assigned-clock-rates = <400000000>;
		resets = <&ccu RST_PCIE_PCLK>, <&ccu RST_PCIE_PWRUP>, <&ccu RST_PCIE_ITS>;
		reset-names = "pclk_rst", "pwrup_rst", "its";
		status = "disabled";

		pcie_intc: legacy-interrupt-controller {
			interrupt-controller;
			#address-cells = <0>;
			#interrupt-cells = <1>;
		};
	};

	thermal-zones {
		cpu_little_thermal: cpu-little-thermal {
			polling-delay-passive = <0>;
			polling-delay = <0>;
			thermal-sensors = <&ths 0>;

			trips {
				cpu_little_passive: cpu-little-passive {
					temperature = <75000>;
					hysteresis = <2000>;
					type = "passive";
				};

				cpu_little_hot: cpu-little-hot {
					temperature = <85000>;
					hysteresis = <2000>;
					type = "passive";
				};

				cpu_little_crit: cpu-little-crit {
					temperature = <105000>;
					hysteresis = <0>;
					type = "critical";
				};
			};
		};

		cpu_big_thermal: cpu-big-thermal {
			polling-delay-passive = <0>;
			polling-delay = <0>;
			thermal-sensors = <&ths 1>;

			trips {
				cpu_big_passive: cpu-big-passive {
					temperature = <75000>;
					hysteresis = <2000>;
					type = "passive";
				};

				cpu_big_hot: cpu-big-hot {
					temperature = <85000>;
					hysteresis = <2000>;
					type = "passive";
				};

				cpu_big_crit: cpu-big-crit {
					temperature = <105000>;
					hysteresis = <0>;
					type = "critical";
				};
			};
		};

		gpu_thermal: gpu-thermal {
			polling-delay-passive = <0>;
			polling-delay = <0>;
			thermal-sensors = <&ths 2>;

			trips {
				gpu_crit: gpu-crit {
					temperature = <105000>;
					hysteresis = <0>;
					type = "critical";
				};
			};
		};

		npu_thermal: npu-thermal {
			polling-delay-passive = <0>;
			polling-delay = <0>;
			thermal-sensors = <&ths 3>;

			trips {
				npu_crit: npu-crit {
					temperature = <105000>;
					hysteresis = <0>;
					type = "critical";
				};
			};
		};

		ddr_thermal: ddr-thermal {
			polling-delay-passive = <0>;
			polling-delay = <0>;
			thermal-sensors = <&ths 4>;

			trips {
				ddr_crit: ddr-crit {
					temperature = <105000>;
					hysteresis = <0>;
					type = "critical";
				};
			};
		};
	};
};
